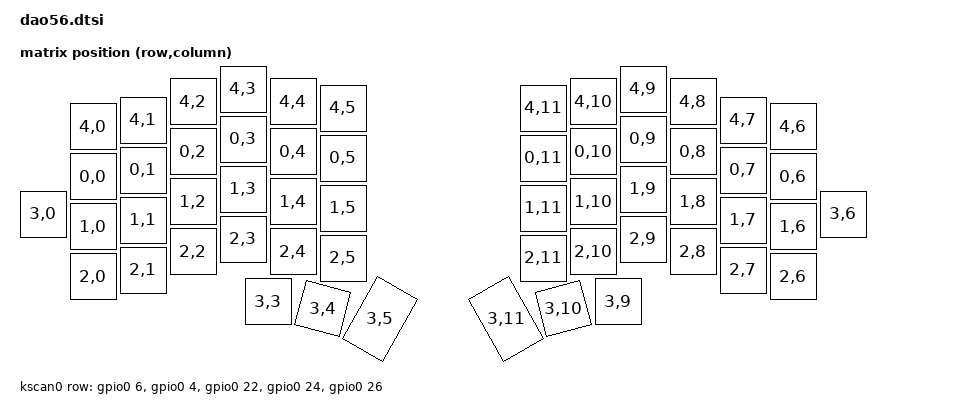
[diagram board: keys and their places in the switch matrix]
/* Dao56 overrides for the shared Dao board module. */
#include <dt-bindings/zmk/matrix_transform.h>

&kscan0 {
    row-gpios = <&gpio0  6 (GPIO_ACTIVE_HIGH | GPIO_PULL_DOWN)>,
                <&gpio0  4 (GPIO_ACTIVE_HIGH | GPIO_PULL_DOWN)>,
                <&gpio0 22 (GPIO_ACTIVE_HIGH | GPIO_PULL_DOWN)>,
                <&gpio0 24 (GPIO_ACTIVE_HIGH | GPIO_PULL_DOWN)>,
                <&gpio0 26 (GPIO_ACTIVE_HIGH | GPIO_PULL_DOWN)>;
};

&extra_keys_transform {
    rows = <5>;
    columns = <14>;
    map = <
        RC(4,0) RC(4,1) RC(4,2) RC(4,3) RC(4,4) RC(4,5)  RC(4,11) RC(4,10) RC(4,9) RC(4,8) RC(4,7) RC(4,6)
        RC(3,0) RC(0,0) RC(0,1) RC(0,2) RC(0,3) RC(0,4) RC(0,5)  RC(0,11) RC(0,10) RC(0,9) RC(0,8) RC(0,7) RC(0,6) RC(3,6)
        RC(1,0) RC(1,1) RC(1,2) RC(1,3) RC(1,4) RC(1,5)  RC(1,11) RC(1,10) RC(1,9) RC(1,8) RC(1,7) RC(1,6)
        RC(2,0) RC(2,1) RC(2,2) RC(2,3) RC(2,4) RC(2,5)  RC(2,11) RC(2,10) RC(2,9) RC(2,8) RC(2,7) RC(2,6)
        RC(3,3) RC(3,4) RC(3,5)  RC(3,11) RC(3,10) RC(3,9)
    >;
};

&vbatt {
    output-ohms = <2000000>;
    full-ohms = <(2000000 + 820000)>;
};

&dao_full_layout {
    display-name = "Dao56";
    // w h x y rotation rotation-center-x rotation-center-y (hundredths)
    keys =
        <&key_physical_attrs 100 100 100 75 0 0 0>,
        <&key_physical_attrs 100 100 200 62 0 0 0>,
        <&key_physical_attrs 100 100 300 25 0 0 0>,
        <&key_physical_attrs 100 100 400 0 0 0 0>,
        <&key_physical_attrs 100 100 500 25 0 0 0>,
        <&key_physical_attrs 100 100 600 38 0 0 0>,
        <&key_physical_attrs 100 100 1000 38 0 0 0>,
        <&key_physical_attrs 100 100 1100 25 0 0 0>,
        <&key_physical_attrs 100 100 1200 0 0 0 0>,
        <&key_physical_attrs 100 100 1300 25 0 0 0>,
        <&key_physical_attrs 100 100 1400 62 0 0 0>,
        <&key_physical_attrs 100 100 1500 75 0 0 0>,
        <&key_physical_attrs 100 100 0 250 0 0 0>,
        <&key_physical_attrs 100 100 100 175 0 0 0>,
        <&key_physical_attrs 100 100 200 162 0 0 0>,
        <&key_physical_attrs 100 100 300 125 0 0 0>,
        <&key_physical_attrs 100 100 400 100 0 0 0>,
        <&key_physical_attrs 100 100 500 125 0 0 0>,
        <&key_physical_attrs 100 100 600 138 0 0 0>,
        <&key_physical_attrs 100 100 1000 138 0 0 0>,
        <&key_physical_attrs 100 100 1100 125 0 0 0>,
        <&key_physical_attrs 100 100 1200 100 0 0 0>,
        <&key_physical_attrs 100 100 1300 125 0 0 0>,
        <&key_physical_attrs 100 100 1400 162 0 0 0>,
        <&key_physical_attrs 100 100 1500 175 0 0 0>,
        <&key_physical_attrs 100 100 1600 250 0 0 0>,
        <&key_physical_attrs 100 100 100 275 0 0 0>,
        <&key_physical_attrs 100 100 200 262 0 0 0>,
        <&key_physical_attrs 100 100 300 225 0 0 0>,
        <&key_physical_attrs 100 100 400 200 0 0 0>,
        <&key_physical_attrs 100 100 500 225 0 0 0>,
        <&key_physical_attrs 100 100 600 238 0 0 0>,
        <&key_physical_attrs 100 100 1000 238 0 0 0>,
        <&key_physical_attrs 100 100 1100 225 0 0 0>,
        <&key_physical_attrs 100 100 1200 200 0 0 0>,
        <&key_physical_attrs 100 100 1300 225 0 0 0>,
        <&key_physical_attrs 100 100 1400 262 0 0 0>,
        <&key_physical_attrs 100 100 1500 275 0 0 0>,
        <&key_physical_attrs 100 100 100 375 0 0 0>,
        <&key_physical_attrs 100 100 200 362 0 0 0>,
        <&key_physical_attrs 100 100 300 325 0 0 0>,
        <&key_physical_attrs 100 100 400 300 0 0 0>,
        <&key_physical_attrs 100 100 500 325 0 0 0>,
        <&key_physical_attrs 100 100 600 338 0 0 0>,
        <&key_physical_attrs 100 100 1000 338 0 0 0>,
        <&key_physical_attrs 100 100 1100 325 0 0 0>,
        <&key_physical_attrs 100 100 1200 300 0 0 0>,
        <&key_physical_attrs 100 100 1300 325 0 0 0>,
        <&key_physical_attrs 100 100 1400 362 0 0 0>,
        <&key_physical_attrs 100 100 1500 375 0 0 0>,
        <&key_physical_attrs 100 100 450 425 0 0 0>,
        <&key_physical_attrs 100 100 450 425 1500 500 898>,
        <&key_physical_attrs 100 150 450 375 3000 500 898>,
        <&key_physical_attrs 100 150 1150 375 (-3000) 1200 898>,
        <&key_physical_attrs 100 100 1150 425 (-1500) 1200 898>,
        <&key_physical_attrs 100 100 1150 425 0 0 0>;
};

// Dao56 uses one physical layout; the module's 42-key layout is incompatible.
/delete-node/ &dao_crkbd_layout;

&layouts_dao_position_map {
    /delete-node/ crkbd;
    dao {
        positions = <0 1 2 3 4 5 6 7 8 9 10 11 12 13 14 15 16 17 18 19 20 21 22 23 24 25 26 27 28 29 30 31 32 33 34 35 36 37 38 39 40 41 42 43 44 45 46 47 48 49 50 51 52 53 54 55>;
    };
};
